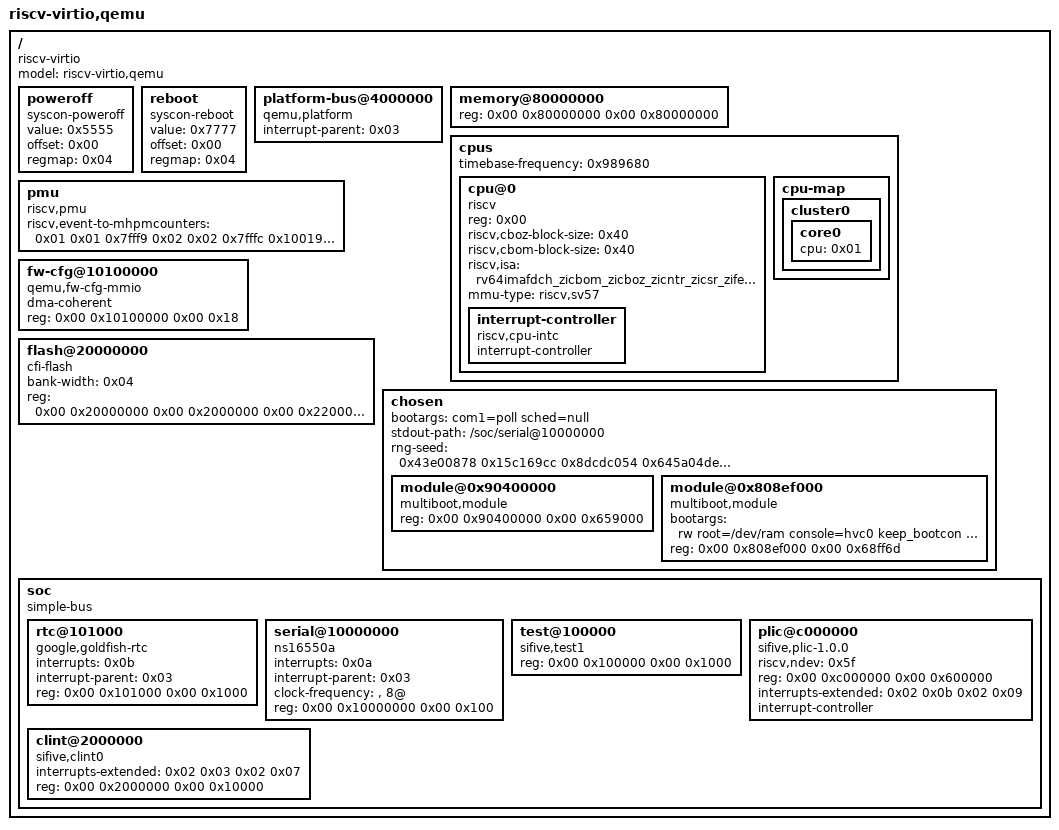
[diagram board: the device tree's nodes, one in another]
/dts-v1/;

/ {
	#address-cells = <0x02>;
	#size-cells = <0x02>;
	compatible = "riscv-virtio";
	model = "riscv-virtio,qemu";

	poweroff {
		value = <0x5555>;
		offset = <0x00>;
		regmap = <0x04>;
		compatible = "syscon-poweroff";
	};

	reboot {
		value = <0x7777>;
		offset = <0x00>;
		regmap = <0x04>;
		compatible = "syscon-reboot";
	};

	platform-bus@4000000 {
		interrupt-parent = <0x03>;
		ranges = <0x00 0x00 0x4000000 0x2000000>;
		#address-cells = <0x01>;
		#size-cells = <0x01>;
		compatible = "qemu,platform", "simple-bus";
	};

	memory@80000000 {
		device_type = "memory";
		reg = <0x00 0x80000000 0x00 0x80000000>;
	};

	cpus {
		#address-cells = <0x01>;
		#size-cells = <0x00>;
		timebase-frequency = <0x989680>;

		cpu@0 {
			phandle = <0x01>;
			device_type = "cpu";
			reg = <0x00>;
			status = "okay";
			compatible = "riscv";
			riscv,cboz-block-size = <0x40>;
			riscv,cbom-block-size = <0x40>;
			riscv,isa = "rv64imafdch_zicbom_zicboz_zicntr_zicsr_zifencei_zihintntl_zihintpause_zihpm_zawrs_zfa_zca_zcd_zba_zbb_zbc_zbs_sstc_svadu";
			mmu-type = "riscv,sv57";

			interrupt-controller {
				#interrupt-cells = <0x01>;
				interrupt-controller;
				compatible = "riscv,cpu-intc";
				phandle = <0x02>;
			};
		};

		cpu-map {

			cluster0 {

				core0 {
					cpu = <0x01>;
				};
			};
		};
	};

	pmu {
		riscv,event-to-mhpmcounters = <0x01 0x01 0x7fff9 0x02 0x02 0x7fffc 0x10019 0x10019 0x7fff8 0x1001b 0x1001b 0x7fff8 0x10021 0x10021 0x7fff8>;
		compatible = "riscv,pmu";
	};

	fw-cfg@10100000 {
		dma-coherent;
		reg = <0x00 0x10100000 0x00 0x18>;
		compatible = "qemu,fw-cfg-mmio";
	};

	flash@20000000 {
		bank-width = <0x04>;
		reg = <0x00 0x20000000 0x00 0x2000000 0x00 0x22000000 0x00 0x2000000>;
		compatible = "cfi-flash";
	};

	chosen {
		bootargs = "com1=poll sched=null";
		stdout-path = "/soc/serial@10000000";
		rng-seed = <0x43e00878 0x15c169cc 0x8dcdc054 0x645a04de 0x83689d98 0x6f218b30 0xf6dcf9ca 0xb3433ec9>;

		module@0x90400000 {
			compatible = "multiboot,module", "multiboot,ramdisk";
			reg = <0x00 0x90400000 0x00 0x659000>;
		};

		module@0x808ef000 {
			bootargs = "rw root=/dev/ram console=hvc0 keep_bootcon bootmem_debug debug";
			compatible = "multiboot,module", "multiboot,kernel";
			reg = <0x00 0x808ef000 0x00 0x68ff6d>;
		};
	};

	soc {
		#address-cells = <0x02>;
		#size-cells = <0x02>;
		compatible = "simple-bus";
		ranges;

		rtc@101000 {
			interrupts = <0x0b>;
			interrupt-parent = <0x03>;
			reg = <0x00 0x101000 0x00 0x1000>;
			compatible = "google,goldfish-rtc";
		};

		serial@10000000 {
			interrupts = <0x0a>;
			interrupt-parent = <0x03>;
			clock-frequency = "", "8@";
			reg = <0x00 0x10000000 0x00 0x100>;
			compatible = "ns16550a";
		};

		test@100000 {
			phandle = <0x04>;
			reg = <0x00 0x100000 0x00 0x1000>;
			compatible = "sifive,test1", "sifive,test0", "syscon";
		};

		plic@c000000 {
			phandle = <0x03>;
			riscv,ndev = <0x5f>;
			reg = <0x00 0xc000000 0x00 0x600000>;
			interrupts-extended = <0x02 0x0b 0x02 0x09>;
			interrupt-controller;
			compatible = "sifive,plic-1.0.0", "riscv,plic0";
			#address-cells = <0x00>;
			#interrupt-cells = <0x01>;
		};

		clint@2000000 {
			interrupts-extended = <0x02 0x03 0x02 0x07>;
			reg = <0x00 0x2000000 0x00 0x10000>;
			compatible = "sifive,clint0", "riscv,clint0";
		};
	};
};
